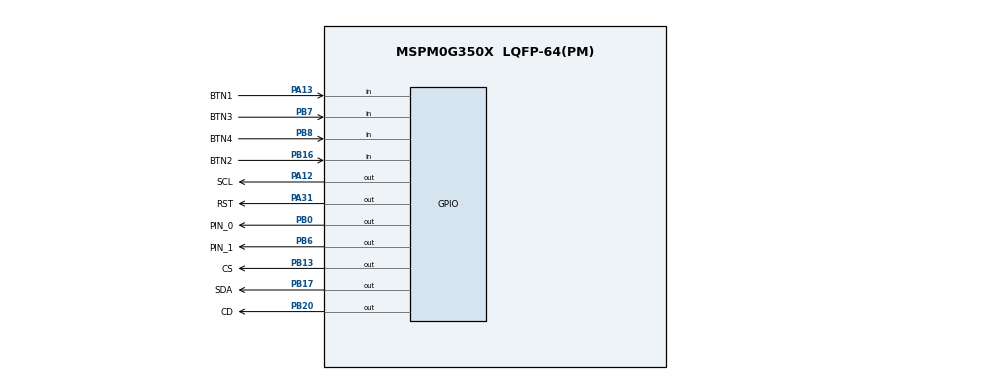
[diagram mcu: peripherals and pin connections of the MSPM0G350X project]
/**
 * @cliArgs --device "MSPM0G350X" --package "LQFP-64(PM)" --part "Default" --product "mspm0_sdk@2.01.00.03"
 * @versions {"tool":"1.20.0+3587"}
 */

/**
 * Import the modules used in this configuration.
 */
const ADC12         = scripting.addModule("/ti/driverlib/ADC12", {}, false);
const ADC121        = ADC12.addInstance();
const ADC122        = ADC12.addInstance();
const COMP          = scripting.addModule("/ti/driverlib/COMP", {}, false);
const COMP1         = COMP.addInstance();
const GPIO          = scripting.addModule("/ti/driverlib/GPIO", {}, false);
const GPIO1         = GPIO.addInstance();
const GPIO2         = GPIO.addInstance();
const GPIO3         = GPIO.addInstance();
const SYSCTL        = scripting.addModule("/ti/driverlib/SYSCTL");
const TIMER         = scripting.addModule("/ti/driverlib/TIMER", {}, false);
const TIMER1        = TIMER.addInstance();
const ProjectConfig = scripting.addModule("/ti/project_config/ProjectConfig");

/**
 * Write custom configuration values to the imported modules.
 */
const divider6       = system.clockTree["PLL_CLK2X_DIV"];
divider6.divideValue = 8;

const multiplier2         = system.clockTree["PLL_QDIV"];
multiplier2.multiplyValue = 4;

const mux4       = system.clockTree["EXHFMUX"];
mux4.inputSelect = "EXHFMUX_XTAL";

const mux8       = system.clockTree["HSCLKMUX"];
mux8.inputSelect = "HSCLKMUX_HFCLK";

const mux12       = system.clockTree["SYSPLLMUX"];
mux12.inputSelect = "zSYSPLLMUX_HFCLK";

const pinFunction4        = system.clockTree["HFXT"];
pinFunction4.inputFreq    = 40;
pinFunction4.enable       = true;
pinFunction4.HFXTStartup  = 20;
pinFunction4.HFCLKMonitor = true;

ADC121.$name                             = "ADC12_0";
ADC121.sampClkSrc                        = "DL_ADC12_CLOCK_ULPCLK";
ADC121.repeatMode                        = true;
ADC121.trigSrc                           = "DL_ADC12_TRIG_SRC_EVENT";
ADC121.adcMem0trig                       = "DL_ADC12_TRIGGER_MODE_TRIGGER_NEXT";
ADC121.powerDownMode                     = "DL_ADC12_POWER_DOWN_MODE_MANUAL";
ADC121.enabledInterrupts                 = ["DL_ADC12_INTERRUPT_DMA_DONE"];
ADC121.configureDMA                      = true;
ADC121.sampCnt                           = 1;
ADC121.enabledDMATriggers                = ["DL_ADC12_DMA_MEM0_RESULT_LOADED"];
ADC121.subChanID                         = 12;
ADC121.sampleTime0                       = "20 us";
ADC121.adcMem0chansel                    = "DL_ADC12_INPUT_CHAN_2";
ADC121.peripheral.$assign                = "ADC0";
ADC121.DMA_CHANNEL.$name                 = "DMA_CH0";
ADC121.DMA_CHANNEL.addressMode           = "f2b";
ADC121.DMA_CHANNEL.srcLength             = "HALF_WORD";
ADC121.DMA_CHANNEL.dstLength             = "HALF_WORD";
ADC121.DMA_CHANNEL.configureTransferSize = true;
ADC121.DMA_CHANNEL.transferMode          = "FULL_CH_REPEAT_SINGLE";
ADC121.DMA_CHANNEL.transferSize          = 1024;
ADC121.DMA_CHANNEL.peripheral.$assign    = "DMA_CH0";
ADC121.adcPin2Config.$name               = "ti_driverlib_gpio_GPIOPinGeneric2";

ADC122.$name                             = "ADC12_1";
ADC122.sampClkSrc                        = "DL_ADC12_CLOCK_ULPCLK";
ADC122.repeatMode                        = true;
ADC122.trigSrc                           = "DL_ADC12_TRIG_SRC_EVENT";
ADC122.powerDownMode                     = "DL_ADC12_POWER_DOWN_MODE_MANUAL";
ADC122.configureDMA                      = true;
ADC122.sampCnt                           = 1;
ADC122.enabledDMATriggers                = ["DL_ADC12_DMA_MEM0_RESULT_LOADED"];
ADC122.subChanID                         = 12;
ADC122.sampleTime0                       = "20 us";
ADC122.adcMem0trig                       = "DL_ADC12_TRIGGER_MODE_TRIGGER_NEXT";
ADC122.adcMem0chansel                    = "DL_ADC12_INPUT_CHAN_6";
ADC122.DMA_CHANNEL.$name                 = "DMA_CH1";
ADC122.DMA_CHANNEL.addressMode           = "f2b";
ADC122.DMA_CHANNEL.srcLength             = "HALF_WORD";
ADC122.DMA_CHANNEL.dstLength             = "HALF_WORD";
ADC122.DMA_CHANNEL.configureTransferSize = true;
ADC122.DMA_CHANNEL.transferMode          = "FULL_CH_REPEAT_SINGLE";
ADC122.DMA_CHANNEL.transferSize          = 1024;
ADC122.adcPin6Config.$name               = "ti_driverlib_gpio_GPIOPinGeneric4";

const Board = scripting.addModule("/ti/driverlib/Board", {}, false);

COMP1.$name                          = "COMP_0";
COMP1.hysteresis                     = "DL_COMP_HYSTERESIS_20";
COMP1.vSource                        = "DL_COMP_REF_SOURCE_VDDA_DAC";
COMP1.terminalSelect                 = "DL_COMP_REF_TERMINAL_SELECT_NEG";
COMP1.controlSelect                  = "DL_COMP_DAC_CONTROL_SW";
COMP1.setDACCode0                    = 0x80;
COMP1.channelEnable                  = ["POS"];
COMP1.enableOutputFilter             = true;
COMP1.enabledInterrupts              = ["DL_COMP_INTERRUPT_OUTPUT_EDGE","DL_COMP_INTERRUPT_OUTPUT_EDGE_INV"];
COMP1.selectOutputFilter             = "DL_COMP_FILTER_DELAY_2700";
COMP1.peripheral.$assign             = "COMP0";
COMP1.peripheral.compPinPos0.$assign = "PA26";
COMP1.compPinPos0Config.$name        = "ti_driverlib_gpio_GPIOPinGeneric0";

GPIO1.$name                         = "GPIO_GAIN_SW";
GPIO1.port                          = "PORTB";
GPIO1.associatedPins.create(2);
GPIO1.associatedPins[0].$name       = "PIN_0";
GPIO1.associatedPins[0].pin.$assign = "PB0";
GPIO1.associatedPins[1].$name       = "PIN_1";
GPIO1.associatedPins[1].pin.$assign = "PB6";

GPIO2.$name                          = "SPI";
GPIO2.associatedPins.create(5);
GPIO2.associatedPins[0].$name        = "CS";
GPIO2.associatedPins[0].assignedPort = "PORTB";
GPIO2.associatedPins[0].pin.$assign  = "PB13";
GPIO2.associatedPins[1].$name        = "CD";
GPIO2.associatedPins[1].pin.$assign  = "PB20";
GPIO2.associatedPins[2].$name        = "RST";
GPIO2.associatedPins[2].pin.$assign  = "PA31";
GPIO2.associatedPins[3].$name        = "SCL";
GPIO2.associatedPins[3].pin.$assign  = "PA12";
GPIO2.associatedPins[4].$name        = "SDA";
GPIO2.associatedPins[4].pin.$assign  = "PB17";

GPIO3.$name                              = "BUTTON";
GPIO3.associatedPins.create(4);
GPIO3.associatedPins[0].$name            = "BTN1";
GPIO3.associatedPins[0].direction        = "INPUT";
GPIO3.associatedPins[0].internalResistor = "PULL_UP";
GPIO3.associatedPins[0].inputFilter      = "8_CYCLES";
GPIO3.associatedPins[0].interruptEn      = true;
GPIO3.associatedPins[0].polarity         = "FALL";
GPIO3.associatedPins[0].pin.$assign      = "PA13";
GPIO3.associatedPins[1].$name            = "BTN2";
GPIO3.associatedPins[1].direction        = "INPUT";
GPIO3.associatedPins[1].inputFilter      = "8_CYCLES";
GPIO3.associatedPins[1].internalResistor = "PULL_UP";
GPIO3.associatedPins[1].interruptEn      = true;
GPIO3.associatedPins[1].polarity         = "FALL";
GPIO3.associatedPins[1].pin.$assign      = "PB16";
GPIO3.associatedPins[2].$name            = "BTN3";
GPIO3.associatedPins[2].direction        = "INPUT";
GPIO3.associatedPins[2].internalResistor = "PULL_UP";
GPIO3.associatedPins[2].inputFilter      = "8_CYCLES";
GPIO3.associatedPins[2].interruptEn      = true;
GPIO3.associatedPins[2].polarity         = "FALL";
GPIO3.associatedPins[2].pin.$assign      = "PB7";
GPIO3.associatedPins[3].$name            = "BTN4";
GPIO3.associatedPins[3].direction        = "INPUT";
GPIO3.associatedPins[3].internalResistor = "PULL_UP";
GPIO3.associatedPins[3].inputFilter      = "8_CYCLES";
GPIO3.associatedPins[3].interruptEn      = true;
GPIO3.associatedPins[3].polarity         = "FALL";
GPIO3.associatedPins[3].pin.$assign      = "PB8";

SYSCTL.forceDefaultClkConfig = true;
SYSCTL.clockTreeEn           = true;

TIMER1.$name                       = "TIMER_0";
TIMER1.timerMode                   = "PERIODIC";
TIMER1.event1PublisherChannel      = 12;
TIMER1.event1ControllerInterruptEn = ["ZERO_EVENT"];
TIMER1.interrupts                  = ["ZERO"];
TIMER1.timerPeriod                 = "200 us";
TIMER1.peripheral.$assign          = "TIMG0";

ProjectConfig.genLibCMSIS = true;

/**
 * Pinmux solution for unlocked pins/peripherals. This ensures that minor changes to the automatic solver in a future
 * version of the tool will not impact the pinmux you originally saw.  These lines can be completely deleted in order to
 * re-solve from scratch.
 */
pinFunction4.peripheral.$suggestSolution           = "SYSCTL";
pinFunction4.peripheral.hfxInPin.$suggestSolution  = "PA5";
pinFunction4.peripheral.hfxOutPin.$suggestSolution = "PA6";
ADC121.peripheral.adcPin2.$suggestSolution         = "PA25";
ADC122.peripheral.$suggestSolution                 = "ADC1";
ADC122.peripheral.adcPin6.$suggestSolution         = "PB19";
ADC122.DMA_CHANNEL.peripheral.$suggestSolution     = "DMA_CH1";
Board.peripheral.$suggestSolution                  = "DEBUGSS";
Board.peripheral.swclkPin.$suggestSolution         = "PA20";
Board.peripheral.swdioPin.$suggestSolution         = "PA19";
